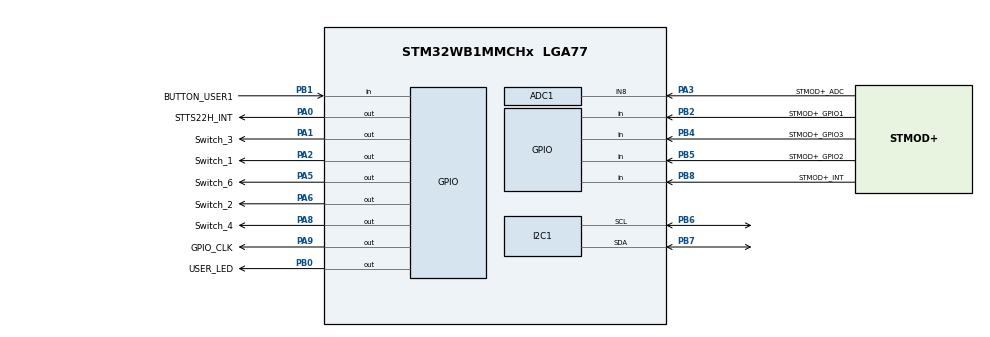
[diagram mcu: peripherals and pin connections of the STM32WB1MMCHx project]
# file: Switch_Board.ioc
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ADC1.Channel-0\#ChannelRegularConversion=ADC_CHANNEL_8
ADC1.NbrOfConversionFlag=1
ADC1.Rank-0\#ChannelRegularConversion=1
ADC1.SamplingTime-0\#ChannelRegularConversion=ADC_SAMPLINGTIME_COMMON_1
ADC1.SelectedChannel=ADC_CHANNEL_8
ADC1.master=1
I2C1.Timing=0x00B07CB4
Mcu.Family=STM32WB
Mcu.Name=STM32WB1MMCHx
Mcu.Package=LGA77
NVIC.HSEM_IRQn=true\:0\:0\:false\:false\:true\:false\:true\:true
NVIC.IPCC_C1_RX_IRQn=true\:0\:0\:false\:false\:true\:true\:true\:true
NVIC.IPCC_C1_TX_IRQn=true\:0\:0\:false\:false\:true\:true\:true\:true
NVIC.PriorityGroup=NVIC_PRIORITYGROUP_4
NVIC.RTC_WKUP_IRQn=true\:0\:0\:false\:false\:true\:true\:true\:true
PA0.GPIO_Label=STTS22H_INT
PA0.Signal=GPIO_Output
PA1.GPIO_Label=Switch_3
PA1.Signal=GPIO_Output
PA10.GPIO_Label=STMOD+_UART1_RX
PA10.Signal=USART1_RX
PA11.GPIO_Label=STMOD+_UART1_CTS
PA11.Signal=USART1_CTS
PA12.GPIO_Label=STMOD+_UART1_RTS
PA12.Signal=USART1_RTS
PA13.Mode=Serial_Wire
PA13.Signal=SYS_JTMS-SWDIO
PA14.Mode=Serial_Wire
PA14.Signal=SYS_JTCK-SWCLK
PA2.GPIO_Label=Switch_1
PA2.Signal=GPIO_Output
PA3.GPIO_Label=STMOD+_ADC
PA3.Signal=ADCx_IN8
PA4.GPIO_Label=Switch_5
PA4.Signal=SPI1_NSS
PA5.GPIO_Label=Switch_6
PA5.Signal=GPIO_Output
PA6.GPIO_Label=Switch_2
PA6.Signal=GPIO_Output
PA7.GPIO_Label=STMOD+_SPI1_MOSIP
PA7.GPIO_PuPd=GPIO_PULLDOWN
PA7.Signal=SPI1_MOSI
PA8.GPIO_Label=Switch_4
PA8.Signal=GPIO_Output
PA9.GPIO_Label=GPIO_CLK
PA9.Signal=GPIO_Output
PB0.GPIO_Label=USER_LED
PB0.GPIO_Speed=GPIO_SPEED_FREQ_HIGH
PB0.Signal=GPIO_Output
PB1.GPIO_Label=BUTTON_USER1
PB1.GPIO_PuPd=GPIO_PULLUP
PB1.Signal=GPIO_Input
PB2.GPIO_Label=STMOD+_GPIO1
PB2.Signal=GPIO_Input
PB4.GPIO_Label=STMOD+_GPIO3
PB4.Signal=GPIO_Input
PB5.GPIO_Label=STMOD+_GPIO2
PB5.Signal=GPIO_Input
PB6.GPIO_Speed=GPIO_SPEED_FREQ_HIGH
PB6.Mode=I2C
PB6.Signal=I2C1_SCL
PB7.GPIO_Speed=GPIO_SPEED_FREQ_HIGH
PB7.Mode=I2C
PB7.Signal=I2C1_SDA
PB8.GPIO_Label=STMOD+_INT
PB8.Signal=GPIO_Input
ProjectManager.HeapSize=0x200
ProjectManager.StackSize=0x400
ProjectManager.TargetToolchain=STM32CubeIDE
RCC.AHBFreq_Value=32000000
RCC.APB1Freq_Value=32000000
RCC.APB1TimFreq_Value=32000000
RCC.APB2Freq_Value=32000000
RCC.APB2TimFreq_Value=32000000
RCC.APB3Freq_Value=16000000
RCC.CortexFreq_Value=32000000
RCC.HCLKFreq_Value=32000000
RCC.HSE_VALUE=32000000
RCC.HSI_VALUE=16000000
RCC.PLLN=24
RCC.PLLR=RCC_PLLR_DIV3
RCC.SYSCLKFreq_VALUE=32000000
RCC.SYSCLKSource=RCC_SYSCLKSOURCE_PLLCLK
RCC.VCOOutputFreq_Value=96000000
SH.ADCx_IN8.0=ADC1_IN8,IN8-Single-Ended
STM32_WPAN.AD_TYPE_COMPLETE_LOCAL_NAME=Switch_Board
STM32_WPAN.AD_TYPE_COMPLETE_LOCAL_NAME_LENGTH=13
STM32_WPAN.CFG_LSCLK_LSE=0
STM32_WPAN.CUSTOM_P2P_SERVER=Disabled
STM32_WPAN.CUSTOM_TEMPLATE=Enabled
STM32_WPAN.INCLUDE_AD_TYPE_COMPLETE_LOCAL_NAME=1
STM32_WPAN.NUMBER_OF_SERVICES=1
STM32_WPAN.SERVICE1_CHAR1_GATT_NOTIFY_READ_REQ_AND_WAIT_FOR_APPL_RESP=\ 
STM32_WPAN.SERVICE1_CHAR1_GATT_NOTIFY_WRITE_REQ_AND_WAIT_FOR_APPL_RESP=\ 
STM32_WPAN.SERVICE1_CHAR1_LONG_NAME=charWrite
STM32_WPAN.SERVICE1_CHAR1_PROP_WRITE=CHAR_PROP_WRITE
STM32_WPAN.SERVICE1_CHAR1_SHORT_NAME=charWrite
STM32_WPAN.SERVICE1_LONG_NAME=EpicService
STM32_WPAN.SERVICE1_SHORT_NAME=EpicService
VP_HSEM_VS_HSEM.Mode=HSEM_Activate
VP_IPCC_VS_IPCC.Mode=IPCC_Activate
VP_MEMORYMAP_VS_MEMORYMAP.Mode=CurAppReg
VP_RCC_V_OSC32_IN.Mode=LSE-External-Clock-Source
VP_RCC_V_OSC_IN.Mode=HSE-External-Clock-Source
VP_RF_VS_RF.Mode=RF_Activate
VP_RTC_VS_RTC_Activate.Mode=RTC_Enabled
VP_RTC_VS_RTC_WakeUp_intern.Mode=WakeUp
VP_SEQUENCER_VS_SEQUENCER.Mode=SEQUENCER_Enabled
VP_STM32_WPAN_VS_BLE_HOST.Mode=STM32_WPAN_Enabled
VP_TINY_LPM_VS_TINY_LPM.Mode=TINY_LPM_Enabled
board=B-WB1M-WPAN1

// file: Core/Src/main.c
/* USER CODE BEGIN Header */
/**
  ******************************************************************************
  * @file           : main.c
  * @brief          : Main program body
  ******************************************************************************
  * @attention
  *
  * Copyright (c) 2025 STMicroelectronics.
  * All rights reserved.
  *
  * This software is licensed under terms that can be found in the LICENSE file
  * in the root directory of this software component.
  * If no LICENSE file comes with this software, it is provided AS-IS.
  *
  ******************************************************************************
  */
/* USER CODE END Header */
#include "main.h"

ADC_HandleTypeDef hadc1;

I2C_HandleTypeDef hi2c1;

IPCC_HandleTypeDef hipcc;

RTC_HandleTypeDef hrtc;

void SystemClock_Config(void);
void PeriphCommonClock_Config(void);
static void MX_GPIO_Init(void);
static void MX_ADC1_Init(void);
static void MX_I2C1_Init(void);
static void MX_IPCC_Init(void);
static void MX_RTC_Init(void);
static void MX_RF_Init(void);

int main(void)
{

  /* MCU Configuration--------------------------------------------------------*/

  /* Reset of all peripherals, Initializes the Flash interface and the Systick. */
  HAL_Init();
  /* Config code for STM32_WPAN (HSE Tuning must be done before system clock configuration) */
  MX_APPE_Config();

  /* Configure the system clock */
  SystemClock_Config();

  /* Configure the peripherals common clocks */
  PeriphCommonClock_Config();

  /* IPCC initialisation */
  MX_IPCC_Init();

  /* Initialize all configured peripherals */
  MX_GPIO_Init();
  MX_ADC1_Init();
  MX_I2C1_Init();
  MX_RTC_Init();
  MX_RF_Init();

  /* Init code for STM32_WPAN */
  MX_APPE_Init();

//  SHCI_CmdStatus_t status;
//  status = SHCI_C2_BLE_Init(&ble_init_cmd_packet);
//  if (status != SHCI_Success) {
      // ERROR CHECK: status 0x07 often means "Memory Capacity Exceeded"
      // This happens if your GATT database is too large for the WB1x "Light" stack.
//      something ();s
      HAL_GPIO_WritePin(GPIOB, GPIO_PIN_0, 1);

  /* Infinite loop */
  /* USER CODE BEGIN WHILE */
  while (1)
  {
	  printf("Hello");
//	  printf("%d\n", (int)APP_BLE_Get_Server_Connection_Status());
//    /* USER CODE END WHILE */
    MX_APPE_Process();

    /* USER CODE BEGIN 3 */
    printf("hello\n");
//  }
  /* USER CODE END 3 */
  }

}
void SystemClock_Config(void)
{
  RCC_OscInitTypeDef RCC_OscInitStruct = {0};
  RCC_ClkInitTypeDef RCC_ClkInitStruct = {0};

  /** Configure LSE Drive Capability
  */
  HAL_PWR_EnableBkUpAccess();
  __HAL_RCC_LSEDRIVE_CONFIG(RCC_LSEDRIVE_MEDIUMHIGH);

  /** Initializes the RCC Oscillators according to the specified parameters
  * in the RCC_OscInitTypeDef structure.
  */
  RCC_OscInitStruct.OscillatorType = RCC_OSCILLATORTYPE_HSI|RCC_OSCILLATORTYPE_LSI1
                              |RCC_OSCILLATORTYPE_HSE|RCC_OSCILLATORTYPE_LSE
                              |RCC_OSCILLATORTYPE_MSI;
  RCC_OscInitStruct.HSEState = RCC_HSE_ON;
  RCC_OscInitStruct.LSEState = RCC_LSE_ON;
  RCC_OscInitStruct.HSIState = RCC_HSI_ON;
  RCC_OscInitStruct.MSIState = RCC_MSI_ON;
  RCC_OscInitStruct.HSICalibrationValue = RCC_HSICALIBRATION_DEFAULT;
  RCC_OscInitStruct.MSICalibrationValue = RCC_MSICALIBRATION_DEFAULT;
  RCC_OscInitStruct.MSIClockRange = RCC_MSIRANGE_6;
  RCC_OscInitStruct.LSIState = RCC_LSI_ON;
  RCC_OscInitStruct.PLL.PLLState = RCC_PLL_ON;
  RCC_OscInitStruct.PLL.PLLSource = RCC_PLLSOURCE_MSI;
  RCC_OscInitStruct.PLL.PLLM = RCC_PLLM_DIV1;
  RCC_OscInitStruct.PLL.PLLN = 24;
  RCC_OscInitStruct.PLL.PLLP = RCC_PLLP_DIV2;
  RCC_OscInitStruct.PLL.PLLR = RCC_PLLR_DIV3;
  RCC_OscInitStruct.PLL.PLLQ = RCC_PLLQ_DIV2;
  if (HAL_RCC_OscConfig(&RCC_OscInitStruct) != HAL_OK)
  {
    Error_Handler();
  }

  /** Configure the SYSCLKSource, HCLK, PCLK1 and PCLK2 clocks dividers
  */
  RCC_ClkInitStruct.ClockType = RCC_CLOCKTYPE_HCLK4|RCC_CLOCKTYPE_HCLK2
                              |RCC_CLOCKTYPE_HCLK|RCC_CLOCKTYPE_SYSCLK
                              |RCC_CLOCKTYPE_PCLK1|RCC_CLOCKTYPE_PCLK2;
  RCC_ClkInitStruct.SYSCLKSource = RCC_SYSCLKSOURCE_PLLCLK;
  RCC_ClkInitStruct.AHBCLKDivider = RCC_SYSCLK_DIV1;
  RCC_ClkInitStruct.APB1CLKDivider = RCC_HCLK_DIV1;
  RCC_ClkInitStruct.APB2CLKDivider = RCC_HCLK_DIV1;
  RCC_ClkInitStruct.AHBCLK2Divider = RCC_SYSCLK_DIV1;
  RCC_ClkInitStruct.AHBCLK4Divider = RCC_SYSCLK_DIV1;

  if (HAL_RCC_ClockConfig(&RCC_ClkInitStruct, FLASH_LATENCY_1) != HAL_OK)
  {
    Error_Handler();
  }

  /** Enable MSI Auto calibration
  */
  HAL_RCCEx_EnableMSIPLLMode();
}

void PeriphCommonClock_Config(void)
{
  RCC_PeriphCLKInitTypeDef PeriphClkInitStruct = {0};

  /** Initializes the peripherals clock
  */
  PeriphClkInitStruct.PeriphClockSelection = RCC_PERIPHCLK_SMPS|RCC_PERIPHCLK_RFWAKEUP;
  PeriphClkInitStruct.RFWakeUpClockSelection = RCC_RFWKPCLKSOURCE_LSE;
  PeriphClkInitStruct.SmpsClockSelection = RCC_SMPSCLKSOURCE_HSI;
  PeriphClkInitStruct.SmpsDivSelection = RCC_SMPSCLKDIV_RANGE1;

  if (HAL_RCCEx_PeriphCLKConfig(&PeriphClkInitStruct) != HAL_OK)
  {
    Error_Handler();
  }
}

static void MX_ADC1_Init(void)
{

  ADC_ChannelConfTypeDef sConfig = {0};

  /** Common config
  */
  hadc1.Instance = ADC1;
  hadc1.Init.ClockPrescaler = ADC_CLOCK_ASYNC_DIV1;
  hadc1.Init.Resolution = ADC_RESOLUTION_12B;
  hadc1.Init.DataAlign = ADC_DATAALIGN_RIGHT;
  hadc1.Init.ScanConvMode = ADC_SCAN_DISABLE;
  hadc1.Init.EOCSelection = ADC_EOC_SINGLE_CONV;
  hadc1.Init.SamplingTimeCommon1 = ADC_SAMPLETIME_1CYCLE_5;
  hadc1.Init.SamplingTimeCommon2 = ADC_SAMPLETIME_1CYCLE_5;
  hadc1.Init.LowPowerAutoWait = DISABLE;
  hadc1.Init.ContinuousConvMode = DISABLE;
  hadc1.Init.NbrOfConversion = 1;
  hadc1.Init.DiscontinuousConvMode = DISABLE;
  hadc1.Init.ExternalTrigConv = ADC_SOFTWARE_START;
  hadc1.Init.ExternalTrigConvEdge = ADC_EXTERNALTRIGCONVEDGE_NONE;
  hadc1.Init.DMAContinuousRequests = DISABLE;
  hadc1.Init.Overrun = ADC_OVR_DATA_PRESERVED;
  if (HAL_ADC_Init(&hadc1) != HAL_OK)
  {
    Error_Handler();
  }

  /** Configure Regular Channel
  */
  sConfig.Channel = ADC_CHANNEL_8;
  sConfig.Rank = ADC_REGULAR_RANK_1;
  sConfig.SamplingTime = ADC_SAMPLINGTIME_COMMON_1;
  if (HAL_ADC_ConfigChannel(&hadc1, &sConfig) != HAL_OK)
  {
    Error_Handler();
  }

}

static void MX_I2C1_Init(void)
{

  hi2c1.Instance = I2C1;
  hi2c1.Init.Timing = 0x00B07CB4;
  hi2c1.Init.OwnAddress1 = 0;
  hi2c1.Init.AddressingMode = I2C_ADDRESSINGMODE_7BIT;
  hi2c1.Init.DualAddressMode = I2C_DUALADDRESS_DISABLE;
  hi2c1.Init.OwnAddress2 = 0;
  hi2c1.Init.OwnAddress2Masks = I2C_OA2_NOMASK;
  hi2c1.Init.GeneralCallMode = I2C_GENERALCALL_DISABLE;
  hi2c1.Init.NoStretchMode = I2C_NOSTRETCH_DISABLE;
  if (HAL_I2C_Init(&hi2c1) != HAL_OK)
  {
    Error_Handler();
  }

  /** Configure Analogue filter
  */
  if (HAL_I2CEx_ConfigAnalogFilter(&hi2c1, I2C_ANALOGFILTER_ENABLE) != HAL_OK)
  {
    Error_Handler();
  }

  /** Configure Digital filter
  */
  if (HAL_I2CEx_ConfigDigitalFilter(&hi2c1, 0) != HAL_OK)
  {
    Error_Handler();
  }

}

static void MX_IPCC_Init(void)
{

  hipcc.Instance = IPCC;
  if (HAL_IPCC_Init(&hipcc) != HAL_OK)
  {
    Error_Handler();
  }

}

static void MX_RF_Init(void)
{

}

static void MX_RTC_Init(void)
{

  /** Initialize RTC Only
  */
  hrtc.Instance = RTC;
  hrtc.Init.HourFormat = RTC_HOURFORMAT_24;
  hrtc.Init.AsynchPrediv = CFG_RTC_ASYNCH_PRESCALER;
  hrtc.Init.SynchPrediv = CFG_RTC_SYNCH_PRESCALER;
  hrtc.Init.OutPut = RTC_OUTPUT_DISABLE;
  hrtc.Init.OutPutPolarity = RTC_OUTPUT_POLARITY_HIGH;
  hrtc.Init.OutPutRemap = RTC_OUTPUT_REMAP_NONE;
  if (HAL_RTC_Init(&hrtc) != HAL_OK)
  {
    Error_Handler();
  }

  /** Enable the WakeUp
  */
  if (HAL_RTCEx_SetWakeUpTimer_IT(&hrtc, 0, RTC_WAKEUPCLOCK_RTCCLK_DIV16) != HAL_OK)
  {
    Error_Handler();
  }

}

static void MX_GPIO_Init(void)
{
  GPIO_InitTypeDef GPIO_InitStruct = {0};

  /* GPIO Ports Clock Enable */
  __HAL_RCC_GPIOA_CLK_ENABLE();
  __HAL_RCC_GPIOB_CLK_ENABLE();

  /*Configure GPIO pin Output Level */
  HAL_GPIO_WritePin(GPIOA, Switch_4_Pin|Switch_3_Pin|Switch_2_Pin|Switch_1_Pin
                          |STTS22H_INT_Pin|GPIO_CLK_Pin|Switch_6_Pin, GPIO_PIN_RESET);

  /*Configure GPIO pin Output Level */
  HAL_GPIO_WritePin(USER_LED_GPIO_Port, USER_LED_Pin, GPIO_PIN_RESET);

  /*Configure GPIO pin : Switch_5_Pin */
  GPIO_InitStruct.Pin = Switch_5_Pin;
  GPIO_InitStruct.Mode = GPIO_MODE_AF_PP;
  GPIO_InitStruct.Pull = GPIO_NOPULL;
  GPIO_InitStruct.Speed = GPIO_SPEED_FREQ_LOW;
  GPIO_InitStruct.Alternate = GPIO_AF5_SPI1;
  HAL_GPIO_Init(Switch_5_GPIO_Port, &GPIO_InitStruct);

  /*Configure GPIO pins : Switch_4_Pin Switch_3_Pin Switch_2_Pin Switch_1_Pin
                           STTS22H_INT_Pin GPIO_CLK_Pin Switch_6_Pin */
  GPIO_InitStruct.Pin = Switch_4_Pin|Switch_3_Pin|Switch_2_Pin|Switch_1_Pin
                          |STTS22H_INT_Pin|GPIO_CLK_Pin|Switch_6_Pin;
  GPIO_InitStruct.Mode = GPIO_MODE_OUTPUT_PP;
  GPIO_InitStruct.Pull = GPIO_NOPULL;
  GPIO_InitStruct.Speed = GPIO_SPEED_FREQ_LOW;
  HAL_GPIO_Init(GPIOA, &GPIO_InitStruct);

  /*Configure GPIO pins : STMOD__INT_Pin STMOD__GPIO2_Pin STMOD__GPIO3_Pin STMOD__GPIO1_Pin */
  GPIO_InitStruct.Pin = STMOD__INT_Pin|STMOD__GPIO2_Pin|STMOD__GPIO3_Pin|STMOD__GPIO1_Pin;
  GPIO_InitStruct.Mode = GPIO_MODE_INPUT;
  GPIO_InitStruct.Pull = GPIO_NOPULL;
  HAL_GPIO_Init(GPIOB, &GPIO_InitStruct);

  /*Configure GPIO pin : STMOD__SPI1_MOSIP_Pin */
  GPIO_InitStruct.Pin = STMOD__SPI1_MOSIP_Pin;
  GPIO_InitStruct.Mode = GPIO_MODE_AF_PP;
  GPIO_InitStruct.Pull = GPIO_PULLDOWN;
  GPIO_InitStruct.Speed = GPIO_SPEED_FREQ_LOW;
  GPIO_InitStruct.Alternate = GPIO_AF5_SPI1;
  HAL_GPIO_Init(STMOD__SPI1_MOSIP_GPIO_Port, &GPIO_InitStruct);

  /*Configure GPIO pins : STMOD__UART1_RTS_Pin STMOD__UART1_CTS_Pin STMOD__UART1_RX_Pin */
  GPIO_InitStruct.Pin = STMOD__UART1_RTS_Pin|STMOD__UART1_CTS_Pin|STMOD__UART1_RX_Pin;
  GPIO_InitStruct.Mode = GPIO_MODE_AF_PP;
  GPIO_InitStruct.Pull = GPIO_NOPULL;
  GPIO_InitStruct.Speed = GPIO_SPEED_FREQ_LOW;
  GPIO_InitStruct.Alternate = GPIO_AF7_USART1;
  HAL_GPIO_Init(GPIOA, &GPIO_InitStruct);

  /*Configure GPIO pin : BUTTON_USER1_Pin */
  GPIO_InitStruct.Pin = BUTTON_USER1_Pin;
  GPIO_InitStruct.Mode = GPIO_MODE_INPUT;
  GPIO_InitStruct.Pull = GPIO_PULLUP;
  HAL_GPIO_Init(BUTTON_USER1_GPIO_Port, &GPIO_InitStruct);

  /*Configure GPIO pin : USER_LED_Pin */
  GPIO_InitStruct.Pin = USER_LED_Pin;
  GPIO_InitStruct.Mode = GPIO_MODE_OUTPUT_PP;
  GPIO_InitStruct.Pull = GPIO_NOPULL;
  GPIO_InitStruct.Speed = GPIO_SPEED_FREQ_HIGH;
  HAL_GPIO_Init(USER_LED_GPIO_Port, &GPIO_InitStruct);

}

void Error_Handler(void)
{
  __disable_irq();
  while (1)
  {
  }
}
